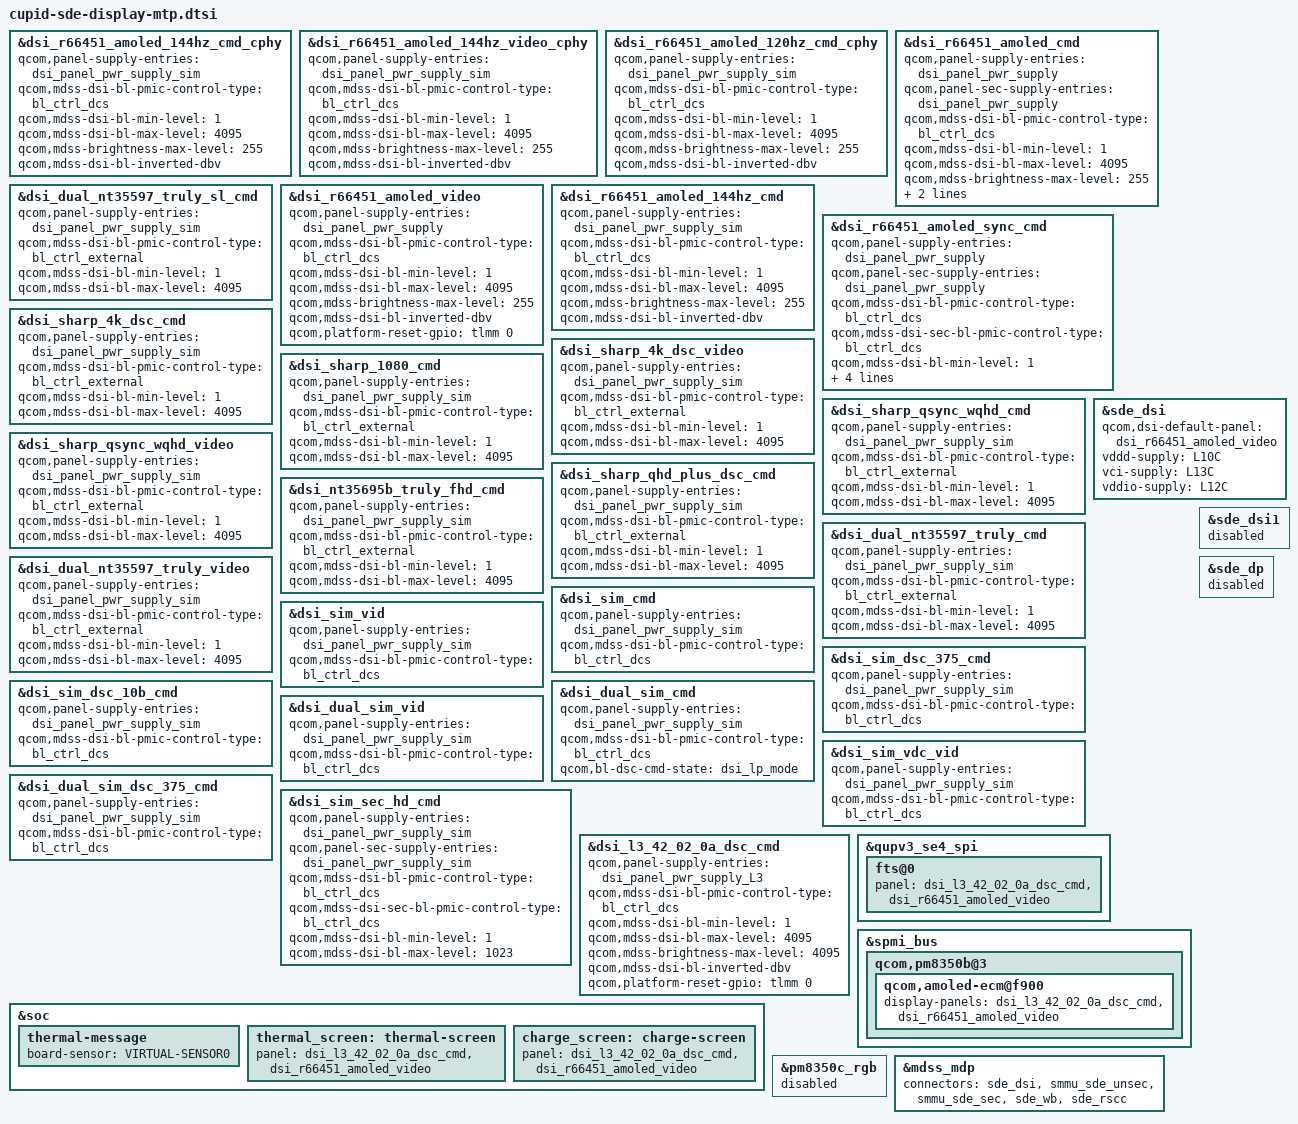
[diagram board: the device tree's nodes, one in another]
#include "waipio-sde-display.dtsi"

&dsi_r66451_amoled_144hz_cmd_cphy {
	qcom,panel-supply-entries = <&dsi_panel_pwr_supply_sim>;
	qcom,mdss-dsi-bl-pmic-control-type = "bl_ctrl_dcs";
	qcom,mdss-dsi-bl-min-level = <1>;
	qcom,mdss-dsi-bl-max-level = <4095>;
	qcom,mdss-brightness-max-level = <255>;
	qcom,mdss-dsi-bl-inverted-dbv;
};

&dsi_r66451_amoled_144hz_video_cphy {
	qcom,panel-supply-entries = <&dsi_panel_pwr_supply_sim>;
	qcom,mdss-dsi-bl-pmic-control-type = "bl_ctrl_dcs";
	qcom,mdss-dsi-bl-min-level = <1>;
	qcom,mdss-dsi-bl-max-level = <4095>;
	qcom,mdss-brightness-max-level = <255>;
	qcom,mdss-dsi-bl-inverted-dbv;
};

&dsi_r66451_amoled_120hz_cmd_cphy {
	qcom,panel-supply-entries = <&dsi_panel_pwr_supply_sim>;
	qcom,mdss-dsi-bl-pmic-control-type = "bl_ctrl_dcs";
	qcom,mdss-dsi-bl-min-level = <1>;
	qcom,mdss-dsi-bl-max-level = <4095>;
	qcom,mdss-brightness-max-level = <255>;
	qcom,mdss-dsi-bl-inverted-dbv;
};

&dsi_r66451_amoled_cmd {
	qcom,panel-supply-entries = <&dsi_panel_pwr_supply>;
	qcom,panel-sec-supply-entries = <&dsi_panel_pwr_supply>;
	qcom,mdss-dsi-bl-pmic-control-type = "bl_ctrl_dcs";
	qcom,mdss-dsi-bl-min-level = <1>;
	qcom,mdss-dsi-bl-max-level = <4095>;
	qcom,mdss-brightness-max-level = <255>;
	qcom,mdss-dsi-bl-inverted-dbv;
	qcom,platform-reset-gpio = <&tlmm 0 0>;
};

&dsi_dual_nt35597_truly_sl_cmd {
	qcom,panel-supply-entries = <&dsi_panel_pwr_supply_sim>;
	qcom,mdss-dsi-bl-pmic-control-type = "bl_ctrl_external";
	qcom,mdss-dsi-bl-min-level = <1>;
	qcom,mdss-dsi-bl-max-level = <4095>;
};

&dsi_r66451_amoled_video {
	qcom,panel-supply-entries = <&dsi_panel_pwr_supply>;
	qcom,mdss-dsi-bl-pmic-control-type = "bl_ctrl_dcs";
	qcom,mdss-dsi-bl-min-level = <1>;
	qcom,mdss-dsi-bl-max-level = <4095>;
	qcom,mdss-brightness-max-level = <255>;
	qcom,mdss-dsi-bl-inverted-dbv;
	qcom,platform-reset-gpio = <&tlmm 0 0>;
};

&dsi_r66451_amoled_144hz_cmd {
	qcom,panel-supply-entries = <&dsi_panel_pwr_supply_sim>;
	qcom,mdss-dsi-bl-pmic-control-type = "bl_ctrl_dcs";
	qcom,mdss-dsi-bl-min-level = <1>;
	qcom,mdss-dsi-bl-max-level = <4095>;
	qcom,mdss-brightness-max-level = <255>;
	qcom,mdss-dsi-bl-inverted-dbv;
};

&dsi_r66451_amoled_sync_cmd {
	qcom,panel-supply-entries = <&dsi_panel_pwr_supply>;
	qcom,panel-sec-supply-entries = <&dsi_panel_pwr_supply>;
	qcom,mdss-dsi-bl-pmic-control-type = "bl_ctrl_dcs";
	qcom,mdss-dsi-sec-bl-pmic-control-type = "bl_ctrl_dcs";
	qcom,mdss-dsi-bl-min-level = <1>;
	qcom,mdss-dsi-bl-max-level = <4095>;
	qcom,mdss-brightness-max-level = <255>;
	qcom,mdss-dsi-bl-inverted-dbv;
	qcom,platform-reset-gpio = <&tlmm 0 0>;
};

&dsi_sharp_4k_dsc_cmd {
	qcom,panel-supply-entries = <&dsi_panel_pwr_supply_sim>;
	qcom,mdss-dsi-bl-pmic-control-type = "bl_ctrl_external";
	qcom,mdss-dsi-bl-min-level = <1>;
	qcom,mdss-dsi-bl-max-level = <4095>;
};

&dsi_sharp_4k_dsc_video {
	qcom,panel-supply-entries = <&dsi_panel_pwr_supply_sim>;
	qcom,mdss-dsi-bl-pmic-control-type = "bl_ctrl_external";
	qcom,mdss-dsi-bl-min-level = <1>;
	qcom,mdss-dsi-bl-max-level = <4095>;
};

&dsi_sharp_1080_cmd {
	qcom,panel-supply-entries = <&dsi_panel_pwr_supply_sim>;
	qcom,mdss-dsi-bl-pmic-control-type = "bl_ctrl_external";
	qcom,mdss-dsi-bl-min-level = <1>;
	qcom,mdss-dsi-bl-max-level = <4095>;
};

&dsi_sharp_qsync_wqhd_cmd {
	qcom,panel-supply-entries = <&dsi_panel_pwr_supply_sim>;
	qcom,mdss-dsi-bl-pmic-control-type = "bl_ctrl_external";
	qcom,mdss-dsi-bl-min-level = <1>;
	qcom,mdss-dsi-bl-max-level = <4095>;
};

&dsi_sharp_qsync_wqhd_video {
	qcom,panel-supply-entries = <&dsi_panel_pwr_supply_sim>;
	qcom,mdss-dsi-bl-pmic-control-type = "bl_ctrl_external";
	qcom,mdss-dsi-bl-min-level = <1>;
	qcom,mdss-dsi-bl-max-level = <4095>;
};

&dsi_sharp_qhd_plus_dsc_cmd {
	qcom,panel-supply-entries = <&dsi_panel_pwr_supply_sim>;
	qcom,mdss-dsi-bl-pmic-control-type = "bl_ctrl_external";
	qcom,mdss-dsi-bl-min-level = <1>;
	qcom,mdss-dsi-bl-max-level = <4095>;
};

&dsi_nt35695b_truly_fhd_cmd {
	qcom,panel-supply-entries = <&dsi_panel_pwr_supply_sim>;
	qcom,mdss-dsi-bl-pmic-control-type = "bl_ctrl_external";
	qcom,mdss-dsi-bl-min-level = <1>;
	qcom,mdss-dsi-bl-max-level = <4095>;
};

&dsi_dual_nt35597_truly_cmd {
	qcom,panel-supply-entries = <&dsi_panel_pwr_supply_sim>;
	qcom,mdss-dsi-bl-pmic-control-type = "bl_ctrl_external";
	qcom,mdss-dsi-bl-min-level = <1>;
	qcom,mdss-dsi-bl-max-level = <4095>;
};

&dsi_dual_nt35597_truly_video {
	qcom,panel-supply-entries = <&dsi_panel_pwr_supply_sim>;
	qcom,mdss-dsi-bl-pmic-control-type = "bl_ctrl_external";
	qcom,mdss-dsi-bl-min-level = <1>;
	qcom,mdss-dsi-bl-max-level = <4095>;
};

&dsi_sim_cmd {
	qcom,panel-supply-entries = <&dsi_panel_pwr_supply_sim>;
	qcom,mdss-dsi-bl-pmic-control-type = "bl_ctrl_dcs";
};

&dsi_sim_vid {
	qcom,panel-supply-entries = <&dsi_panel_pwr_supply_sim>;
	qcom,mdss-dsi-bl-pmic-control-type = "bl_ctrl_dcs";
};

&dsi_sim_dsc_375_cmd {
	qcom,panel-supply-entries = <&dsi_panel_pwr_supply_sim>;
	qcom,mdss-dsi-bl-pmic-control-type = "bl_ctrl_dcs";
};

&dsi_sim_dsc_10b_cmd {
	qcom,panel-supply-entries = <&dsi_panel_pwr_supply_sim>;
	qcom,mdss-dsi-bl-pmic-control-type = "bl_ctrl_dcs";
};

&dsi_dual_sim_cmd {
	qcom,panel-supply-entries = <&dsi_panel_pwr_supply_sim>;
	qcom,mdss-dsi-bl-pmic-control-type = "bl_ctrl_dcs";
	qcom,bl-dsc-cmd-state = "dsi_lp_mode";
};

&dsi_dual_sim_vid {
	qcom,panel-supply-entries = <&dsi_panel_pwr_supply_sim>;
	qcom,mdss-dsi-bl-pmic-control-type = "bl_ctrl_dcs";
};

&dsi_sim_vdc_vid {
	qcom,panel-supply-entries = <&dsi_panel_pwr_supply_sim>;
	qcom,mdss-dsi-bl-pmic-control-type = "bl_ctrl_dcs";
};

&dsi_dual_sim_dsc_375_cmd {
	qcom,panel-supply-entries = <&dsi_panel_pwr_supply_sim>;
	qcom,mdss-dsi-bl-pmic-control-type = "bl_ctrl_dcs";
};

&dsi_sim_sec_hd_cmd {
	qcom,panel-supply-entries = <&dsi_panel_pwr_supply_sim>;
	qcom,panel-sec-supply-entries = <&dsi_panel_pwr_supply_sim>;
	qcom,mdss-dsi-bl-pmic-control-type = "bl_ctrl_dcs";
	qcom,mdss-dsi-sec-bl-pmic-control-type = "bl_ctrl_dcs";
	qcom,mdss-dsi-bl-min-level = <1>;
	qcom,mdss-dsi-bl-max-level = <1023>;
};

&dsi_l3_42_02_0a_dsc_cmd {
	qcom,panel-supply-entries = <&dsi_panel_pwr_supply_L3>;
	qcom,mdss-dsi-bl-pmic-control-type = "bl_ctrl_dcs";
	qcom,mdss-dsi-bl-min-level = <1>;
	qcom,mdss-dsi-bl-max-level = <4095>;
	qcom,mdss-brightness-max-level = <4095>;
	qcom,mdss-dsi-bl-inverted-dbv;
	qcom,platform-reset-gpio = <&tlmm 0 0>;
};

&sde_dsi {
	qcom,dsi-default-panel = <&dsi_r66451_amoled_video>;
	vddd-supply = <&L10C>;
	vci-supply = <&L13C>;
	vddio-supply = <&L12C>;
};

&qupv3_se4_spi {
	fts@0 {
		panel = <&dsi_l3_42_02_0a_dsc_cmd
			&dsi_r66451_amoled_video>;
	};
};

&soc {
	thermal-message {
		board-sensor = "VIRTUAL-SENSOR0";
	};
	thermal_screen: thermal-screen {
		panel = <&dsi_l3_42_02_0a_dsc_cmd
			&dsi_r66451_amoled_video>;
        };
	charge_screen: charge-screen {
		panel = <&dsi_l3_42_02_0a_dsc_cmd
			&dsi_r66451_amoled_video>;
	};
};

&spmi_bus {
	qcom,pm8350b@3 {
		qcom,amoled-ecm@f900 {
			display-panels = <&dsi_l3_42_02_0a_dsc_cmd
					&dsi_r66451_amoled_video>;
		};
	};
};

&sde_dsi1 {
	status = "disabled";
};

&sde_dp {
	status = "disabled";
};

&pm8350c_rgb {
	status = "disabled";
};

&mdss_mdp {
        connectors = <&sde_dsi &smmu_sde_unsec &smmu_sde_sec &sde_wb &sde_rscc>;
};
